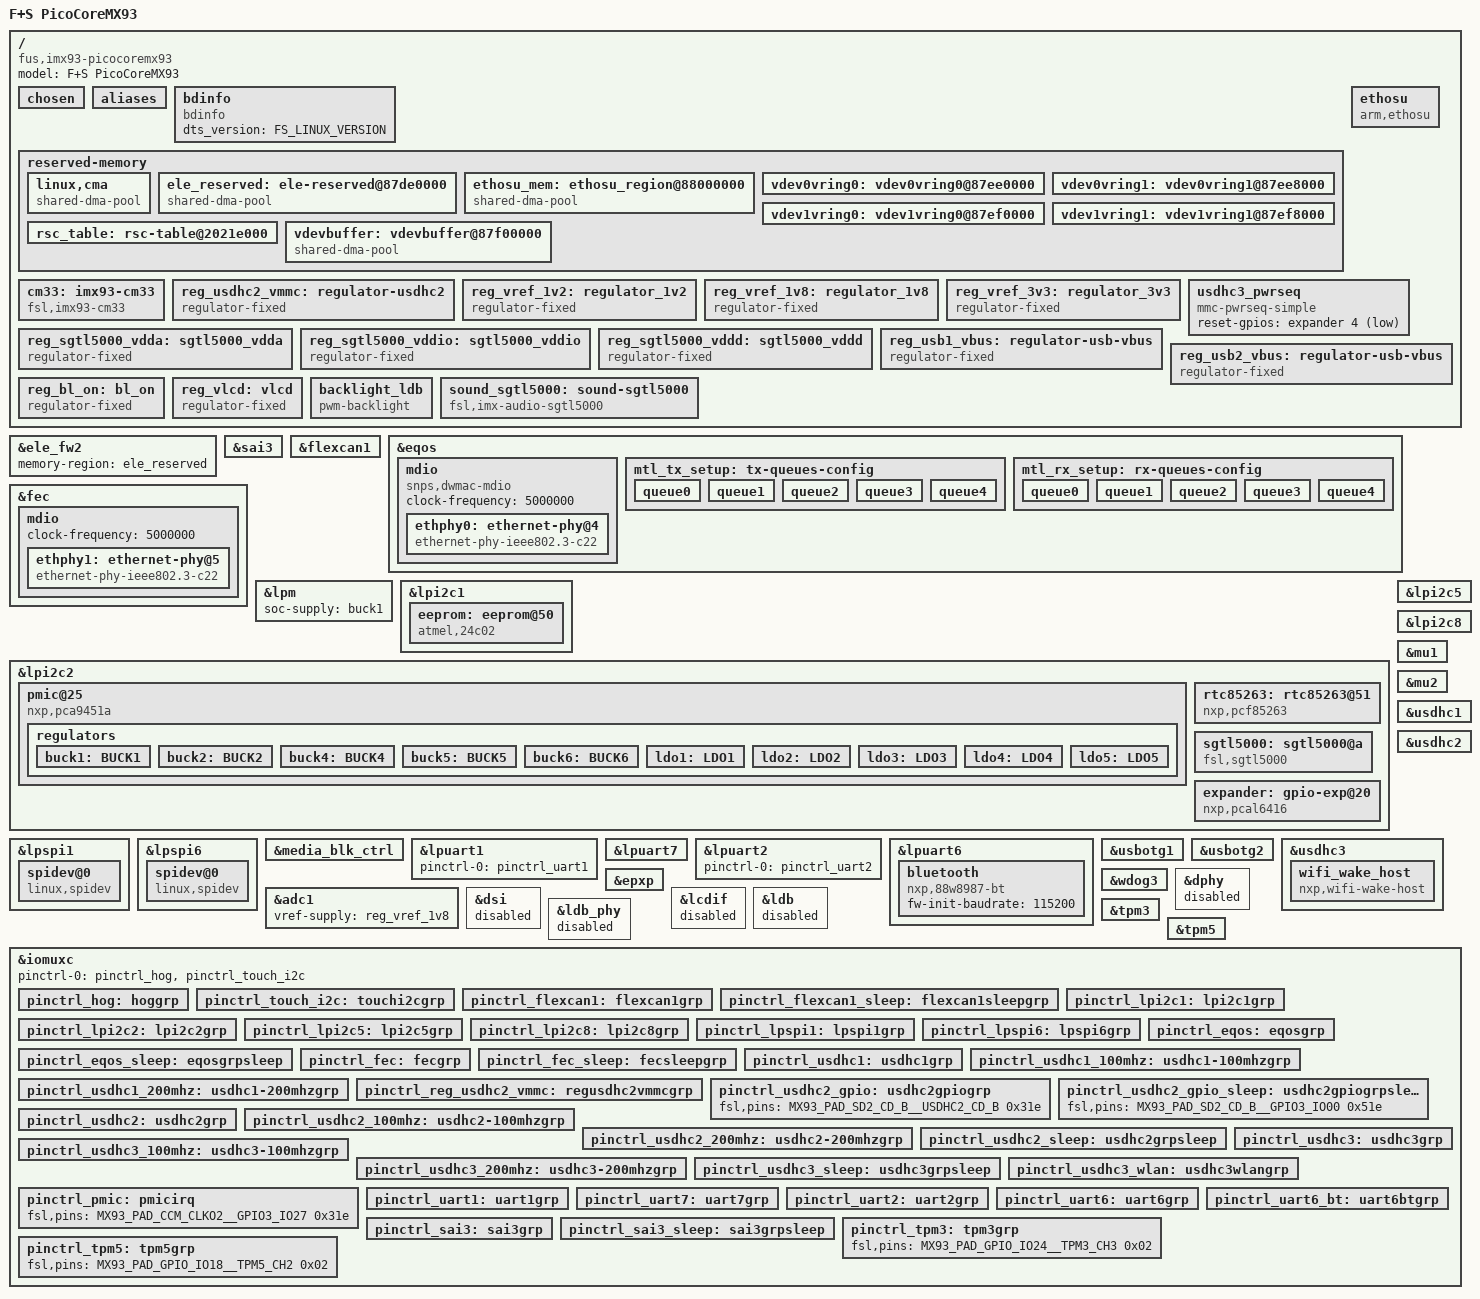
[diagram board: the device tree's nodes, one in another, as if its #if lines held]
/*
 * Copyright (C) 2024 F&S Elektronik Systeme GmbH
 *
 * This program is free software; you can redistribute it and/or modify
 * it under the terms of the GNU General Public License version 2 as
 * published by the Free Software Foundation.
 */

/dts-v1/;

#include <dt-bindings/usb/pd.h>
#include <dt-bindings/pwm/pwm.h>
#include <dt-bindings/rtc/pcf85363.h>
#include "../freescale/imx93.dtsi"
#include <fsversion.h>

&ele_fw2 {
	memory-region = <&ele_reserved>;
};

/ {
	model = "F+S PicoCoreMX93";
	compatible = "fus,imx93-picocoremx93", "fsl,imx93";

	chosen {
		bootargs = "console=ttyLP6,115200";
		stdout-path = &lpuart7;
	};

	aliases {
		ethernet0 = &eqos;
		ethernet1 = &fec;
		spi0 = &lpspi3;
		spi1 = &lpspi6;
		eeprom = &eeprom;
#ifdef CONFIG_PICOCOREMX93_EXT_RTC
		rtcpcf85263 = &rtc85263;
#endif
		sd_a = &usdhc2;
		sd_b = &usdhc3;
		sd_c = &usdhc1;
		adc  = &adc1;
	};

	/* -------------------- BOARD INFO -------------------- */
	bdinfo: bdinfo {
		compatible = "bdinfo";
		dts_version = FS_LINUX_VERSION;
	};

	reserved-memory {
		#address-cells = <2>;
		#size-cells = <2>;
		ranges;

		linux,cma {
			compatible = "shared-dma-pool";
			reusable;
			alloc-ranges = <0 0x80000000 0 0x40000000>;
			size = <0 0x10000000>;
			linux,cma-default;
		};


		ele_reserved: ele-reserved@87de0000 {
			compatible = "shared-dma-pool";
			reg = <0 0x87de0000 0 0x100000>;
			no-map;
		};

#ifdef SUPPORT_RPMSG
		ethosu_mem: ethosu_region@88000000 {
			compatible = "shared-dma-pool";
			reusable;
			reg = <0x0 0x88000000 0x0 0x8000000>;
		};

		vdev0vring0: vdev0vring0@87ee0000 {
			reg = <0 0x87ee0000 0 0x8000>;
			no-map;
		};

		vdev0vring1: vdev0vring1@87ee8000 {
			reg = <0 0x87ee8000 0 0x8000>;
			no-map;
		};

		vdev1vring0: vdev1vring0@87ef0000 {
			reg = <0 0x87ef0000 0 0x8000>;
			no-map;
		};

		vdev1vring1: vdev1vring1@87ef8000 {
			reg = <0 0x87ef8000 0 0x8000>;
			no-map;
		};

		rsc_table: rsc-table@2021e000 {
			reg = <0 0x2021e000 0 0x1000>;
			no-map;
		};

		vdevbuffer: vdevbuffer@87f00000 {
			compatible = "shared-dma-pool";
			reg = <0 0x87f00000 0 0x100000>;
			no-map;
		};
#endif /* SUPPORT_RPMSG */
	};

#ifdef SUPPORT_M33
	cm33: imx93-cm33 {
		compatible = "fsl,imx93-cm33";
#ifdef SUPPORT_RPMSG
		mbox-names = "tx", "rx", "rxdb";
		mboxes = <&mu1 0 1
			  &mu1 1 1
			  &mu1 3 1>;
		memory-region = <&vdevbuffer>, <&vdev0vring0>, <&vdev0vring1>,
				<&vdev1vring0>, <&vdev1vring1>, <&rsc_table>;
#endif /* SUPPORT_RPMSG */
		fsl,startup-delay-ms = <500>;
	};

	ethosu {
		compatible = "arm,ethosu";
		fsl,cm33-proc = <&cm33>;
		memory-region = <&ethosu_mem>;
		power-domains = <&mlmix>;
	};
#endif /* SUPPORT_M33 */

#ifdef CONFIG_PICOCOREMX93_SD_A
	reg_usdhc2_vmmc: regulator-usdhc2 {
		compatible = "regulator-fixed";
		pinctrl-names = "default";
		pinctrl-0 = <&pinctrl_reg_usdhc2_vmmc>;
		regulator-name = "VSD_3V3";
		regulator-min-microvolt = <3300000>;
		regulator-max-microvolt = <3300000>;
		gpio = <&gpio3 7 GPIO_ACTIVE_HIGH>;
		startup-delay-us = <100>;
		off-on-delay-us = <12000>;
		enable-active-high;
	};
#endif /* CONFIG_PICOCOREMX93_SD_A */

	reg_vref_1v2: regulator_1v2 {
		compatible = "regulator-fixed";
		regulator-name = "vref-1V2";
		regulator-min-microvolt = <1200000>;
		regulator-max-microvolt = <1200000>;
		regulator-always-on;
	};

	reg_vref_1v8: regulator_1v8 {
		compatible = "regulator-fixed";
		regulator-name = "vref-1V8";
		regulator-min-microvolt = <1800000>;
		regulator-max-microvolt = <1800000>;
		regulator-always-on;
	};

	reg_vref_3v3: regulator_3v3 {
		compatible = "regulator-fixed";
		regulator-name = "vref-3V3";
		regulator-min-microvolt = <3300000>;
		regulator-max-microvolt = <3300000>;
		regulator-always-on;
	};
#ifdef CONFIG_PICOCOREMX93_SD_B
	usdhc3_pwrseq: usdhc3_pwrseq {
		compatible = "mmc-pwrseq-simple";
		reset-gpios = <&expander 4 GPIO_ACTIVE_LOW>;
	};
#endif /* CONFIG_PICOCOREMX93_SD_B */
#ifdef CONFIG_PICOCOREMX93_SGTL5000_AUDIO
	/* SGTL5000 analog voltage */
	reg_sgtl5000_vdda: sgtl5000_vdda {
		compatible = "regulator-fixed";
		regulator-name = "VDDA-supply";
		regulator-min-microvolt = <3300000>;
		regulator-max-microvolt = <3300000>;
		regulator-always-on;
	};

	/* SGTL5000 I/O voltage */
	reg_sgtl5000_vddio: sgtl5000_vddio {
		compatible = "regulator-fixed";
		regulator-name = "VDDIO-supply";
		regulator-min-microvolt = <3300000>;
		regulator-max-microvolt = <3300000>;
		regulator-always-on;
	};

	/* SGTL5000 internal digital voltage */
	reg_sgtl5000_vddd: sgtl5000_vddd {
		compatible = "regulator-fixed";
		regulator-name = "VDDD-supply";
		regulator-min-microvolt = <1800000>;
		regulator-max-microvolt = <1800000>;
		regulator-always-on;
	};
#endif /* CONFIG_PICOCOREMX93_SGTL5000_AUDIO */

	reg_usb1_vbus: regulator-usb-vbus {
		compatible = "regulator-fixed";
		regulator-name = "usb1_vbus";
		regulator-min-microvolt = <3300000>;
		regulator-max-microvolt = <3300000>;
		gpio = <&expander 3 GPIO_ACTIVE_HIGH>;
		enable-active-high;
	};

	reg_usb2_vbus: regulator-usb-vbus {
		compatible = "regulator-fixed";
		regulator-name = "usb2_vbus";
		regulator-min-microvolt = <3300000>;
		regulator-max-microvolt = <3300000>;
		gpio = <&expander 2 GPIO_ACTIVE_HIGH>;
		enable-active-high;
	};

#ifdef CONFIG_PICOCOREMX93_BL_CTRL
	reg_bl_on: bl_on {
		compatible = "regulator-fixed";
		regulator-name = "BL_ON";
		gpio = <&expander 5 GPIO_ACTIVE_HIGH>;
		regulator-min-microvolt = <3300000>;
		regulator-max-microvolt = <3300000>;
		enable-active-high;
	};
#endif /* CONFIG_PICOCOREMX93_BL_CTRL */

	/* LCD power on voltage */
	reg_vlcd: vlcd {
		compatible = "regulator-fixed";
		regulator-name = "VLCD_ON";
		gpio = <&expander 6 GPIO_ACTIVE_HIGH>;
		regulator-min-microvolt = <3300000>;
		regulator-max-microvolt = <3300000>;
		enable-active-high;
	};

#ifdef CONFIG_PICOCOREMX93_BL_CTRL
	backlight_ldb: backlight_ldb {
		compatible = "pwm-backlight";
		#pwm-cells = <3>;
		pwms = <&tpm5 2 5263157 PWM_POLARITY_INVERTED>;
		power-supply = <&reg_bl_on>;
		brightness-levels = <0 1 5 10 18 28 41 56
			                 73 92 113 137 163 192 222 255>;
		default-brightness-level = <14>;
		fb-names = "mxs-lcdif0";
		status = "okay";
	};
#endif /* CONFIG_PICOCOREMX93_BL_CTRL */

#ifdef CONFIG_PICOCOREMX93_SGTL5000_AUDIO
	sound_sgtl5000: sound-sgtl5000 {
		compatible = "fsl,imx-audio-sgtl5000";
		model = "imx-sgtl5000";
		audio-cpu = <&sai3>;
		audio-codec = <&sgtl5000>;
		audio-routing =
			"LINE_IN", "Line In Jack",
			"Mic Jack", "Mic Bias",
			"MIC_IN", "Mic Jack",
			"Line Out Jack", "LINE_OUT",
			"Headphone Jack", "HP_OUT";
	};
#endif /* CONFIG_PICOCOREMX93_SGTL5000_AUDIO */
};

#ifdef CONFIG_PICOCOREMX93_I2S_A
&sai3 {
	pinctrl-names = "default";
	pinctrl-0 = <&pinctrl_sai3>;
	assigned-clocks = <&clk IMX93_CLK_SAI3>;
	assigned-clock-parents = <&clk IMX93_CLK_AUDIO_PLL>;
	assigned-clock-rates = <24576000>;
	fsl,sai-mclk-direction-output;
	status = "okay";
};
#endif /* CONFIG_PICOCOREMX93_I2S_A */

#ifdef CONFIG_PICOCOREMX93_CAN
&flexcan1 {
	pinctrl-names = "default", "sleep";
	pinctrl-0 = <&pinctrl_flexcan1>;
	pinctrl-1 = <&pinctrl_flexcan1_sleep>;
	status = "okay";
};
#endif /* CONFIG_PICOCOREMX93_CAN */

/* ETH_A */
&eqos {
	pinctrl-names = "default", "sleep";
	pinctrl-0 = <&pinctrl_eqos>;
	pinctrl-1 = <&pinctrl_eqos_sleep>;
	phy-mode = "rgmii-id";
	phy-handle = <&ethphy0>;
	snps,force_thresh_dma_mode;
	snps,mtl-tx-config = <&mtl_tx_setup>;
	snps,mtl-rx-config = <&mtl_rx_setup>;
	status = "okay";

	mdio {
		compatible = "snps,dwmac-mdio";
		#address-cells = <1>;
		#size-cells = <0>;
		clock-frequency = <5000000>;

		ethphy0: ethernet-phy@4 {
			compatible = "ethernet-phy-ieee802.3-c22";
			reg = <4>;
			rtl821x,clkout-disable;
			rtl821x,aldps-enable;
			rtl821x,ssc-rxc-enable;
			rtl821x,ssc-sysclk-enable;
			rtl821x,ssc-clkout-enable;
#ifdef CONFIG_PICOCOREMX93_ETH_A_LED_LINK
			rtl821x,led-link = <2>; // LED2 for link indication
#endif
#ifdef CONFIG_PICOCOREMX93_ETH_A_LED_ACT
			rtl821x,led-act = <1>; // LED1 for activity
#endif
			reset-gpios = <&expander 0 GPIO_ACTIVE_LOW>;
			reset-assert-us = <10000>;
			reset-deassert-us = <50000>;
			interrupt-parent = <&gpio2>;
			interrupts = <28 IRQ_TYPE_LEVEL_LOW>;
			eee-broken-1000t;
		};
	};

	mtl_tx_setup: tx-queues-config {
		snps,tx-queues-to-use = <5>;
		snps,tx-sched-sp;
		queue0 {
			snps,dcb-algorithm;
			snps,priority = <0x1>;
		};
		queue1 {
			snps,dcb-algorithm;
			snps,priority = <0x2>;
		};
		queue2 {
			snps,dcb-algorithm;
			snps,priority = <0x4>;
		};
		queue3 {
			snps,dcb-algorithm;
			snps,priority = <0x8>;
		};
		queue4 {
			snps,dcb-algorithm;
			snps,priority = <0xf0>;
		};
	};

	mtl_rx_setup: rx-queues-config {
		snps,rx-queues-to-use = <5>;
		snps,rx-sched-sp;
		queue0 {
			snps,dcb-algorithm;
			snps,priority = <0x1>;
			snps,map-to-dma-channel = <0>;
		};
		queue1 {
			snps,dcb-algorithm;
			snps,priority = <0x2>;
			snps,map-to-dma-channel = <1>;
		};
		queue2 {
			snps,dcb-algorithm;
			snps,priority = <0x4>;
			snps,map-to-dma-channel = <2>;
		};
		queue3 {
			snps,dcb-algorithm;
			snps,priority = <0x8>;
			snps,map-to-dma-channel = <3>;
		};
		queue4 {
			snps,dcb-algorithm;
			snps,priority = <0xf0>;
			snps,map-to-dma-channel = <4>;
		};
	};
};

/* ETH_B */
&fec {
	pinctrl-names = "default", "sleep";
	pinctrl-0 = <&pinctrl_fec>;
	pinctrl-1 = <&pinctrl_fec_sleep>;
	phy-mode = "rgmii-id";
	phy-handle = <&ethphy1>;
	fsl,magic-packet;
	status = "okay";

	mdio {
		#address-cells = <1>;
		#size-cells = <0>;
		clock-frequency = <5000000>;

		ethphy1: ethernet-phy@5 {
			compatible = "ethernet-phy-ieee802.3-c22";
			reg = <5>;
			rtl821x,clkout-disable;
			rtl821x,aldps-enable;
			rtl821x,ssc-rxc-enable;
			rtl821x,ssc-sysclk-enable;
			rtl821x,ssc-clkout-enable;
#ifdef CONFIG_PICOCOREMX93_ETH_B_LED_LINK
			rtl821x,led-link = <2>; // LED2 for link indication
#endif
#ifdef CONFIG_PICOCOREMX93_ETH_B_LED_ACT
			rtl821x,led-act = <1>; // LED1 for activity
#endif
			reset-gpios = <&expander 1 GPIO_ACTIVE_LOW>;
			reset-assert-us = <10000>;
			reset-deassert-us = <50000>;
			interrupt-parent = <&gpio2>;
			interrupts = <29 IRQ_TYPE_LEVEL_LOW>;
			eee-broken-1000t;
		};
	};
};

&lpm {
	soc-supply = <&buck1>;
	status = "okay";
};

#ifdef CONFIG_PICOCOREMX93_I2C_A
&lpi2c1 {
	#address-cells = <1>;
	#size-cells = <0>;
	clock-frequency = <400000>;
	pinctrl-names = "default", "sleep";
	pinctrl-0 = <&pinctrl_lpi2c1>;
	pinctrl-1 = <&pinctrl_lpi2c1>;
	status = "okay";

	eeprom: eeprom@50 {
		compatible = "atmel,24c02";
		vcc-supply = <&reg_vref_3v3>;
		reg = <0x50>;
		pagesize = <32>;
	};
};
#endif /* CONFIG_PICOCOREMX93_I2C_A */

#ifdef CONFIG_PICOCOREMX93_I2C_D
/* I2C_D */
&lpi2c2 {
	#address-cells = <1>;
	#size-cells = <0>;
	clock-frequency = <400000>;
	pinctrl-names = "default", "sleep";
	pinctrl-0 = <&pinctrl_lpi2c2>;
	pinctrl-1 = <&pinctrl_lpi2c2>;
	status = "okay";

	pmic@25 {
		compatible = "nxp,pca9451a";
		reg = <0x25>;
		pinctrl-names = "default";
		pinctrl-0 = <&pinctrl_pmic>;
		interrupt-parent = <&gpio3>;
		interrupts = <27 IRQ_TYPE_EDGE_FALLING>;

		regulators {
			buck1: BUCK1 {
				regulator-name = "BUCK1";
				regulator-min-microvolt = <650000>;
				regulator-max-microvolt = <2237500>;
				regulator-boot-on;
				regulator-always-on;
				regulator-ramp-delay = <3125>;
			};

			buck2: BUCK2 {
				regulator-name = "BUCK2";
				regulator-min-microvolt = <600000>;
				regulator-max-microvolt = <2187500>;
				regulator-boot-on;
				regulator-always-on;
				regulator-ramp-delay = <3125>;
			};

			buck4: BUCK4{
				regulator-name = "BUCK4";
				regulator-min-microvolt = <600000>;
				regulator-max-microvolt = <3400000>;
				regulator-boot-on;
				regulator-always-on;
			};

			buck5: BUCK5{
				regulator-name = "BUCK5";
				regulator-min-microvolt = <600000>;
				regulator-max-microvolt = <3400000>;
				regulator-boot-on;
				regulator-always-on;
			};

			buck6: BUCK6 {
				regulator-name = "BUCK6";
				regulator-min-microvolt = <600000>;
				regulator-max-microvolt = <3400000>;
				regulator-boot-on;
				regulator-always-on;
			};

			ldo1: LDO1 {
				regulator-name = "LDO1";
				regulator-min-microvolt = <1600000>;
				regulator-max-microvolt = <1900000>;
				regulator-boot-on;
				regulator-always-on;
			};

			ldo2: LDO2 {
				regulator-name = "LDO2";
				regulator-min-microvolt = <800000>;
				regulator-max-microvolt = <1150000>;
				regulator-boot-on;
				regulator-always-on;
			};

			ldo3: LDO3 {
				regulator-name = "LDO3";
				regulator-min-microvolt = <800000>;
				regulator-max-microvolt = <3300000>;
				regulator-boot-on;
				regulator-always-on;
			};

			ldo4: LDO4 {
				regulator-name = "LDO4";
				regulator-min-microvolt = <800000>;
				regulator-max-microvolt = <3300000>;
				regulator-boot-on;
				regulator-always-on;
			};

			ldo5: LDO5 {
				regulator-name = "LDO5";
				regulator-min-microvolt = <1800000>;
				regulator-max-microvolt = <3300000>;
				regulator-boot-on;
				regulator-always-on;
			};
		};
	};

#ifdef CONFIG_PICOCOREMX93_EXT_RTC
	rtc85263: rtc85263@51 {
		compatible = "nxp,pcf85263";
		reg = <0x51>;
		clock-out = <PCF85363_COF_32768Hz>;
		quartz-load-femtofarads = <PCF85363_CAP_12p5pF>;
		quartz-drive-strength = <PCF85363_OSC_DRIVE_LOW>;
	};
#endif

#ifdef CONFIG_PICOCOREMX93_SGTL5000_AUDIO
	sgtl5000: sgtl5000@a {
		#sound-dai-cells = <0>;
		compatible = "fsl,sgtl5000";
		clocks = <&clk IMX93_CLK_SAI3_GATE>;
		reg = <0xa>;
		mono2both;
		VDDA-supply = <&reg_sgtl5000_vdda>;
		VDDIO-supply = <&reg_sgtl5000_vddio>;
		VDDD-supply = <&reg_sgtl5000_vddd>;
		status = "okay";
	};
#endif

		expander: gpio-exp@20 {
			compatible = "nxp,pcal6416";
			reg = <0x20>;
			vcc-supply = <&reg_vref_3v3>;
			gpio-controller;
			#gpio-cells = <2>;
			ngpios = <16>;
			interrupt-parent = <&gpio4>;
			interrupts = <29 IRQ_TYPE_LEVEL_LOW>;
			gpio-line-names = "eth_a_rst",
				"eth_b_rst", "usb_host_pwr",
				"usb_otg_pwr", "wlan_rst",
				"disp_bl_en", "disp_vdd_en", /* bl_on, vlcd_on */
				"gpio_j1_52", "gpio_j1_54",
				"gpio_j2_65", "gpio_j2_67",
				"gpio_j2_69", "gpio_j2_83",
				"gpio_j2_85", "gpio_j1_44",
				"gpio_j1_46";
		};
};
#endif /* CONFIG_PICOCOREMX93_I2C_D */

#ifdef CONFIG_PICOCOREMX93_I2C_C
&lpi2c5 {
	#address-cells = <1>;
	#size-cells = <0>;
	clock-frequency = <400000>;
	pinctrl-names = "default", "sleep";
	pinctrl-0 = <&pinctrl_lpi2c5>;
	pinctrl-1 = <&pinctrl_lpi2c5>;

	status = "okay";
};
#endif /* CONFIG_PICOCOREMX93_I2C_C */

#ifdef CONFIG_PICOCOREMX93_I2C_B
&lpi2c8 {
	#address-cells = <1>;
	#size-cells = <0>;
	clock-frequency = <400000>;
	pinctrl-names = "default", "sleep";
	pinctrl-0 = <&pinctrl_lpi2c8>;
	pinctrl-1 = <&pinctrl_lpi2c8>;

	status = "okay";
};
#endif /* CONFIG_PICOCOREMX93_I2C_B */

#ifdef CONFIG_PICOCOREMX93_SPI_B
&lpspi1 {
	fsl,spi-num-chipselects = <1>;
	pinctrl-names = "default", "sleep";
	pinctrl-0 = <&pinctrl_lpspi1>;
	pinctrl-1 = <&pinctrl_lpspi1>;
	cs-gpios = <&gpio1 11 GPIO_ACTIVE_LOW>;
	status = "okay";

	spidev@0 {
		compatible = "linux,spidev";
		spi-max-frequency = <20000000>;
		reg = <0>;
		status = "okay";
	};
};
#endif /* CONFIG_PICOCOREMX93_SPI_B */

#ifdef CONFIG_PICOCOREMX93_SPI_A
&lpspi6 {
	fsl,spi-num-chipselects = <1>;
	pinctrl-names = "default", "sleep";
	pinctrl-0 = <&pinctrl_lpspi6>;
	pinctrl-1 = <&pinctrl_lpspi6>;
	cs-gpios = <&gpio2 1 GPIO_ACTIVE_LOW>;
	status = "okay";

	spidev@0 {
		compatible = "linux,spidev";
		spi-max-frequency = <20000000>;
		reg = <0>;
		status = "okay";
	};
};
#endif /* CONFIG_PICOCOREMX93_SPI_A */

&media_blk_ctrl {
	status = "okay";
};

&mu1 {
	status = "okay";
};

&mu2 {
	status = "okay";
};

#ifdef CONFIG_PICOCOREMX93_UART_C
&lpuart1 {
	pinctrl-names = "default";
	pinctrl-0 = <&pinctrl_uart1>;
	status = "okay";
};
#endif /* CONFIG_PICOCOREMX93_UART_C */

#ifdef CONFIG_PICOCOREMX93_UART_A
&lpuart7 { /* console */
	pinctrl-names = "default";
	pinctrl-0 = <&pinctrl_uart7>;
#ifdef CONFIG_PICOCOREMX93_UART_A_RTSCTS
	fsl,uart-has-rtscts;
#endif /* CONFIG_PICOCOREMX93_UART_A_RTSCTS */
	status = "okay";
};
#endif

#ifdef CONFIG_PICOCOREMX93_UART_D
&lpuart2 {
	pinctrl-names = "default";
	pinctrl-0 = <&pinctrl_uart2>;
	status = "okay";
};
#endif

#ifdef CONFIG_PICOCOREMX93_UART_B
&lpuart6 {
	/* BT */
	pinctrl-names = "default";
	pinctrl-0 = <&pinctrl_uart6>, <&pinctrl_uart6_bt>;
	status = "okay";
#ifdef CONFIG_PICOCOREMX93_UART_B_RTSCTS
	uart-has-rtscts;
#endif /* CONFIG_PICOCOREMX93_UART_B_RTSCTS */
#ifdef CONFIG_PICOCOREMX93_UART_B_BT
	bluetooth {
		compatible = "nxp,88w8987-bt";
		fw-init-baudrate = <115200>;
	};
#endif /* CONFIG_PICOCOREMX93_UART_B_BT */
};
#endif /* CONFIG_PICOCOREMX93_UART_B */

&usbotg1 {
	dr_mode = "otg";
	vbus-supply = <&reg_usb1_vbus>;
	hnp-disable;
	srp-disable;
	adp-disable;
	disable-over-current;
	samsung,picophy-pre-emp-curr-control = <3>;
	samsung,picophy-dc-vol-level-adjust = <7>;
	status = "okay";
};

&usbotg2 {
	dr_mode = "host";
	vbus-supply = <&reg_usb2_vbus>;
	disable-over-current;
	samsung,picophy-pre-emp-curr-control = <3>;
	samsung,picophy-dc-vol-level-adjust = <7>;
	status = "okay";
};

/* SD_C - eMMC */
&usdhc1 {
	pinctrl-names = "default", "state_100mhz", "state_200mhz";
	pinctrl-0 = <&pinctrl_usdhc1>;
	pinctrl-1 = <&pinctrl_usdhc1_100mhz>;
	pinctrl-2 = <&pinctrl_usdhc1_200mhz>;
	bus-width = <8>;
	non-removable;
	status = "okay";
};

#ifdef CONFIG_PICOCOREMX93_SD_A
&usdhc2 {
	pinctrl-names = "default", "state_100mhz", "state_200mhz", "sleep";
	pinctrl-0 = <&pinctrl_usdhc2>, <&pinctrl_usdhc2_gpio>;
	pinctrl-1 = <&pinctrl_usdhc2_100mhz>, <&pinctrl_usdhc2_gpio>;
	pinctrl-2 = <&pinctrl_usdhc2_200mhz>, <&pinctrl_usdhc2_gpio>;
	pinctrl-3 = <&pinctrl_usdhc2_sleep>, <&pinctrl_usdhc2_gpio_sleep>;
	vmmc-supply = <&reg_usdhc2_vmmc>;
	bus-width = <4>;
	disable-wp;
	status = "okay";
};
#endif /* CONFIG_PICOCOREMX93_SD_A */

#ifdef CONFIG_PICOCOREMX93_SD_B
&usdhc3 {
	pinctrl-names = "default", "state_100mhz", "state_200mhz", "sleep";
	pinctrl-0 = <&pinctrl_usdhc3>, <&pinctrl_usdhc3_wlan>;
	pinctrl-1 = <&pinctrl_usdhc3_100mhz>, <&pinctrl_usdhc3_wlan>;
	pinctrl-2 = <&pinctrl_usdhc3_200mhz>, <&pinctrl_usdhc3_wlan>;
	pinctrl-3 = <&pinctrl_usdhc3_sleep>, <&pinctrl_usdhc3_wlan>;
	mmc-pwrseq = <&usdhc3_pwrseq>;
	vmmc-supply = <&reg_vref_3v3>;
	vqmmc-supply = <&reg_vref_1v8>;
	vqmmc-1-8-v;
	bus-width = <4>;
	keep-power-in-suspend;
	non-removable;
	wakeup-source;
// 	fsl,sdio-async-interrupt-enabled;
//	pm-ignore-notify;
	status = "okay";

	wifi_wake_host {
		compatible = "nxp,wifi-wake-host";
		interrupt-parent = <&gpio3>;
		interrupts = <26 IRQ_TYPE_LEVEL_LOW>;
		interrupt-names = "host-wake";
	};
};
#endif /* CONFIG_PICOCOREMX93_SD_B */

#ifdef CONFIG_PICOCOREMX93_ADC
&adc1 {
	vref-supply = <&reg_vref_1v8>;
	status = "okay";
};
#endif /* CONFIG_PICOCOREMX93_ADC */

&epxp {
	status = "okay";
};

&wdog3 {
	status = "okay";
};

&dphy {
	status = "disabled";
};

&dsi {
	status = "disabled";
};

&lcdif {
	status = "disabled";
};

&ldb {
	status = "disabled";
};

&ldb_phy {
	status = "disabled";
};

#ifdef CONFIG_PICOCOREMX93_PWM_A
&tpm3 {
	pinctrl-names = "default";
	pinctrl-0 = <&pinctrl_tpm3>;
	#pwm-cells = <3>;
	keep-power;
	status = "okay";
};
#endif /* CONFIG_PICOCOREMX93_PWM_A */

#ifdef CONFIG_PICOCOREMX93_BL_CTRL
&tpm5 {
	pinctrl-names = "default";
	pinctrl-0 = <&pinctrl_tpm5>;
	#pwm-cells = <3>;
	keep-power;
	status = "okay";
};
#endif /* CONFIG_PICOCOREMX93_BL_CTRL */

&iomuxc {
	pinctrl-names = "default";
	pinctrl-0 = <&pinctrl_hog>, <&pinctrl_touch_i2c>;

	pinctrl_hog: hoggrp {
		fsl,pins = <
#ifndef CONFIG_PICOCOREMX93_SPI_B
			/* GPIO pins if SPI_B is not used */
			MX93_PAD_SAI1_TXFS__GPIO1_IO11		0x3fe
			MX93_PAD_SAI1_TXC__GPIO1_IO12		0x3fe
			MX93_PAD_SAI1_RXD0__GPIO1_IO14		0x3fe
			MX93_PAD_SAI1_TXD0__GPIO1_IO13		0x3fe
#endif
			/* GPIO expander irq */
			MX93_PAD_CCM_CLKO4__GPIO4_IO29		0x3fe
			/* GPIO_J1_7, MIPI_RESET */
			MX93_PAD_GPIO_IO14__GPIO2_IO14		0x3fe
		>;
	};

	pinctrl_touch_i2c: touchi2cgrp {
	fsl,pins = <
			/* I2C_B_IRQ */
			MX93_PAD_GPIO_IO15__GPIO2_IO15		0x3fe
			/* GPIO_J1_2, TOUCH_RESET */
			MX93_PAD_GPIO_IO19__GPIO2_IO19		0x3fe
		>;
	};

#ifdef CONFIG_PICOCOREMX93_CAN
	pinctrl_flexcan1: flexcan1grp {
		fsl,pins = <
			MX93_PAD_PDM_CLK__CAN1_TX	0x139e
			MX93_PAD_PDM_BIT_STREAM0__CAN1_RX	0x139e
		>;
	};

	pinctrl_flexcan1_sleep: flexcan1sleepgrp {
		fsl,pins = <
			MX93_PAD_PDM_CLK__GPIO1_IO08	0x31e
			MX93_PAD_PDM_BIT_STREAM0__GPIO1_IO09	0x31e
		>;
	};
#endif

#ifdef CONFIG_PICOCOREMX93_I2C_A
	pinctrl_lpi2c1: lpi2c1grp {
		fsl,pins = <
			MX93_PAD_I2C1_SCL__LPI2C1_SCL			0x40000b9e
			MX93_PAD_I2C1_SDA__LPI2C1_SDA			0x40000b9e
		>;
	};
#endif /* CONFIG_PICOCOREMX93_I2C_A */

#ifdef CONFIG_PICOCOREMX93_I2C_D
	pinctrl_lpi2c2: lpi2c2grp {
		fsl,pins = <
			MX93_PAD_I2C2_SCL__LPI2C2_SCL			0x40000b9e
			MX93_PAD_I2C2_SDA__LPI2C2_SDA			0x40000b9e
		>;
	};
#endif /* CONFIG_PICOCOREMX93_I2C_D */

#ifdef CONFIG_PICOCOREMX93_I2C_C
	pinctrl_lpi2c5: lpi2c5grp {
		fsl,pins = <
			MX93_PAD_GPIO_IO23__LPI2C5_SCL			0x40000b9e
			MX93_PAD_GPIO_IO22__LPI2C5_SDA			0x40000b9e
		>;
	};
#endif /* CONFIG_PICOCOREMX93_I2C_C */

#ifdef CONFIG_PICOCOREMX93_I2C_B
	pinctrl_lpi2c8: lpi2c8grp {
		fsl,pins = <
			MX93_PAD_GPIO_IO13__LPI2C8_SCL			0x40000b9e
			MX93_PAD_GPIO_IO12__LPI2C8_SDA			0x40000b9e
		>;
	};
#endif /* CONFIG_PICOCOREMX93_I2C_B */

#ifdef CONFIG_PICOCOREMX93_SPI_B
	pinctrl_lpspi1: lpspi1grp {
		fsl,pins = <
			/*MX93_PAD_SAI1_TXFS__LPSPI1_PCS0		0x3fe */
			MX93_PAD_SAI1_TXFS__GPIO1_IO11		0x3fe
			MX93_PAD_SAI1_TXC__LPSPI1_SIN		0x3fe
			MX93_PAD_SAI1_RXD0__LPSPI1_SOUT		0x3fe
			MX93_PAD_SAI1_TXD0__LPSPI1_SCK		0x3fe
		>;
	};
#endif /* CONFIG_PICOCOREMX93_SPI_B */

#ifdef CONFIG_PICOCOREMX93_SPI_A
	pinctrl_lpspi6: lpspi6grp {
		fsl,pins = <
			/* MX93_PAD_GPIO_IO00__LPSPI6_PCS0	0x3fe */
			MX93_PAD_GPIO_IO00__GPIO2_IO00	0x3fe
			MX93_PAD_GPIO_IO01__LPSPI6_SIN	0x3fe
			MX93_PAD_GPIO_IO02__LPSPI6_SOUT	0x3fe
			MX93_PAD_GPIO_IO03__LPSPI6_SCK	0x3fe
		>;
	};
#endif /* CONFIG_PICOCOREMX93_SPI_A */

	pinctrl_eqos: eqosgrp {
		fsl,pins = <
			MX93_PAD_ENET1_MDC__ENET_QOS_MDC			0x57e
			MX93_PAD_ENET1_MDIO__ENET_QOS_MDIO			0x57e
			MX93_PAD_ENET1_RD0__ENET_QOS_RGMII_RD0			0x57e
			MX93_PAD_ENET1_RD1__ENET_QOS_RGMII_RD1			0x57e
			MX93_PAD_ENET1_RD2__ENET_QOS_RGMII_RD2			0x57e
			MX93_PAD_ENET1_RD3__ENET_QOS_RGMII_RD3			0x57e
			MX93_PAD_ENET1_RXC__CCM_ENET_QOS_CLOCK_GENERATE_RX_CLK	0x58e
			MX93_PAD_ENET1_RX_CTL__ENET_QOS_RGMII_RX_CTL		0x57e
			MX93_PAD_ENET1_TD0__ENET_QOS_RGMII_TD0			0x57e
			MX93_PAD_ENET1_TD1__ENET_QOS_RGMII_TD1			0x57e
			MX93_PAD_ENET1_TD2__ENET_QOS_RGMII_TD2			0x57e
			MX93_PAD_ENET1_TD3__ENET_QOS_RGMII_TD3			0x57e
			MX93_PAD_ENET1_TXC__CCM_ENET_QOS_CLOCK_GENERATE_TX_CLK	0x58e
			MX93_PAD_ENET1_TX_CTL__ENET_QOS_RGMII_TX_CTL		0x57e
			/* ETH_A_PHY_IRQ */
			MX93_PAD_GPIO_IO28__GPIO2_IO28		0x31e
		>;
	};

	pinctrl_eqos_sleep: eqosgrpsleep {
		fsl,pins = <
			MX93_PAD_ENET1_MDC__GPIO4_IO00			0x31e
			MX93_PAD_ENET1_MDIO__GPIO4_IO01			0x31e
			MX93_PAD_ENET1_RD0__GPIO4_IO10			0x31e
			MX93_PAD_ENET1_RD1__GPIO4_IO11			0x31e
			MX93_PAD_ENET1_RD2__GPIO4_IO12			0x31e
			MX93_PAD_ENET1_RD3__GPIO4_IO13			0x31e
			MX93_PAD_ENET1_RXC__GPIO4_IO09			0x31e
			MX93_PAD_ENET1_RX_CTL__GPIO4_IO08			0x31e
			MX93_PAD_ENET1_TD0__GPIO4_IO05			0x31e
			MX93_PAD_ENET1_TD1__GPIO4_IO04			0x31e
			MX93_PAD_ENET1_TD2__GPIO4_IO03			0x31e
			MX93_PAD_ENET1_TD3__GPIO4_IO02			0x31e
			MX93_PAD_ENET1_TXC__GPIO4_IO07			0x31e
			MX93_PAD_ENET1_TX_CTL__GPIO4_IO06			0x31e
			/* ETH_A_PHY_IRQ */
			MX93_PAD_GPIO_IO28__GPIO2_IO28			0x31e
		>;
	};

	pinctrl_fec: fecgrp {
		fsl,pins = <
			MX93_PAD_ENET2_MDC__ENET1_MDC			0x57e
			MX93_PAD_ENET2_MDIO__ENET1_MDIO			0x57e
			MX93_PAD_ENET2_RD0__ENET1_RGMII_RD0		0x57e
			MX93_PAD_ENET2_RD1__ENET1_RGMII_RD1		0x57e
			MX93_PAD_ENET2_RD2__ENET1_RGMII_RD2		0x57e
			MX93_PAD_ENET2_RD3__ENET1_RGMII_RD3		0x57e
			MX93_PAD_ENET2_RXC__ENET1_RGMII_RXC		0x58e
			MX93_PAD_ENET2_RX_CTL__ENET1_RGMII_RX_CTL	0x57e
			MX93_PAD_ENET2_TD0__ENET1_RGMII_TD0		0x57e
			MX93_PAD_ENET2_TD1__ENET1_RGMII_TD1		0x57e
			MX93_PAD_ENET2_TD2__ENET1_RGMII_TD2		0x57e
			MX93_PAD_ENET2_TD3__ENET1_RGMII_TD3		0x57e
			MX93_PAD_ENET2_TXC__ENET1_RGMII_TXC		0x58e
			MX93_PAD_ENET2_TX_CTL__ENET1_RGMII_TX_CTL	0x57e
			/* ETH_B_PHY_IRQ */
			MX93_PAD_GPIO_IO29__GPIO2_IO29		0x31e
		>;
	};

	pinctrl_fec_sleep: fecsleepgrp {
		fsl,pins = <
			MX93_PAD_ENET2_MDC__GPIO4_IO14			0x51e
			MX93_PAD_ENET2_MDIO__GPIO4_IO15			0x51e
			MX93_PAD_ENET2_RD0__GPIO4_IO24			0x51e
			MX93_PAD_ENET2_RD1__GPIO4_IO25			0x51e
			MX93_PAD_ENET2_RD2__GPIO4_IO26			0x51e
			MX93_PAD_ENET2_RD3__GPIO4_IO27			0x51e
			MX93_PAD_ENET2_RXC__GPIO4_IO23			0x51e
			MX93_PAD_ENET2_RX_CTL__GPIO4_IO22			0x51e
			MX93_PAD_ENET2_TD0__GPIO4_IO19			0x51e
			MX93_PAD_ENET2_TD1__GPIO4_IO18			0x51e
			MX93_PAD_ENET2_TD2__GPIO4_IO17			0x51e
			MX93_PAD_ENET2_TD3__GPIO4_IO16			0x51e
			MX93_PAD_ENET2_TXC__GPIO4_IO21			0x51e
			MX93_PAD_ENET2_TX_CTL__GPIO4_IO20			0x51e
			/* ETH_B_PHY_IRQ */
			MX93_PAD_GPIO_IO29__GPIO2_IO29			0x31e
		>;
	};

	/* need to config the SION for data and cmd pad, refer to ERR052021 */
	pinctrl_usdhc1: usdhc1grp {
		fsl,pins = <
			MX93_PAD_SD1_CLK__USDHC1_CLK		0x1582
			MX93_PAD_SD1_CMD__USDHC1_CMD		0x40001382
			MX93_PAD_SD1_DATA0__USDHC1_DATA0	0x40001382
			MX93_PAD_SD1_DATA1__USDHC1_DATA1	0x40001382
			MX93_PAD_SD1_DATA2__USDHC1_DATA2	0x40001382
			MX93_PAD_SD1_DATA3__USDHC1_DATA3	0x40001382
			MX93_PAD_SD1_DATA4__USDHC1_DATA4	0x40001382
			MX93_PAD_SD1_DATA5__USDHC1_DATA5	0x40001382
			MX93_PAD_SD1_DATA6__USDHC1_DATA6	0x40001382
			MX93_PAD_SD1_DATA7__USDHC1_DATA7	0x40001382
			MX93_PAD_SD1_STROBE__USDHC1_STROBE	0x1582
		>;
	};

	/* need to config the SION for data and cmd pad, refer to ERR052021 */
	pinctrl_usdhc1_100mhz: usdhc1-100mhzgrp {
		fsl,pins = <
			MX93_PAD_SD1_CLK__USDHC1_CLK		0x158e
			MX93_PAD_SD1_CMD__USDHC1_CMD		0x4000138e
			MX93_PAD_SD1_DATA0__USDHC1_DATA0	0x4000138e
			MX93_PAD_SD1_DATA1__USDHC1_DATA1	0x4000138e
			MX93_PAD_SD1_DATA2__USDHC1_DATA2	0x4000138e
			MX93_PAD_SD1_DATA3__USDHC1_DATA3	0x4000138e
			MX93_PAD_SD1_DATA4__USDHC1_DATA4	0x4000138e
			MX93_PAD_SD1_DATA5__USDHC1_DATA5	0x4000138e
			MX93_PAD_SD1_DATA6__USDHC1_DATA6	0x4000138e
			MX93_PAD_SD1_DATA7__USDHC1_DATA7	0x4000138e
			MX93_PAD_SD1_STROBE__USDHC1_STROBE	0x158e
		>;
	};

	/* need to config the SION for data and cmd pad, refer to ERR052021 */
	pinctrl_usdhc1_200mhz: usdhc1-200mhzgrp {
		fsl,pins = <
			MX93_PAD_SD1_CLK__USDHC1_CLK		0x15fe
			MX93_PAD_SD1_CMD__USDHC1_CMD		0x400013fe
			MX93_PAD_SD1_DATA0__USDHC1_DATA0	0x400013fe
			MX93_PAD_SD1_DATA1__USDHC1_DATA1	0x400013fe
			MX93_PAD_SD1_DATA2__USDHC1_DATA2	0x400013fe
			MX93_PAD_SD1_DATA3__USDHC1_DATA3	0x400013fe
			MX93_PAD_SD1_DATA4__USDHC1_DATA4	0x400013fe
			MX93_PAD_SD1_DATA5__USDHC1_DATA5	0x400013fe
			MX93_PAD_SD1_DATA6__USDHC1_DATA6	0x400013fe
			MX93_PAD_SD1_DATA7__USDHC1_DATA7	0x400013fe
			MX93_PAD_SD1_STROBE__USDHC1_STROBE	0x15fe
		>;
	};

#ifdef CONFIG_PICOCOREMX93_SD_A
	pinctrl_reg_usdhc2_vmmc: regusdhc2vmmcgrp {
		fsl,pins = <
			MX93_PAD_SD2_RESET_B__GPIO3_IO07	0x31e
		>;
	};

	pinctrl_usdhc2_gpio: usdhc2gpiogrp {
		fsl,pins = <
			/* MX93_PAD_SD2_CD_B__GPIO3_IO00		0x31e */
			MX93_PAD_SD2_CD_B__USDHC2_CD_B		0x31e
		>;
	};

	pinctrl_usdhc2_gpio_sleep: usdhc2gpiogrpsleep {
		fsl,pins = <
			MX93_PAD_SD2_CD_B__GPIO3_IO00		0x51e
		>;
	};

	/* need to config the SION for data and cmd pad, refer to ERR052021 */
	pinctrl_usdhc2: usdhc2grp {
		fsl,pins = <
			MX93_PAD_SD2_CLK__USDHC2_CLK		0x178e
			MX93_PAD_SD2_CMD__USDHC2_CMD		0x4000139e
			MX93_PAD_SD2_DATA0__USDHC2_DATA0	0x40001382
			MX93_PAD_SD2_DATA1__USDHC2_DATA1	0x40001382
			MX93_PAD_SD2_DATA2__USDHC2_DATA2	0x40001382
			MX93_PAD_SD2_DATA3__USDHC2_DATA3	0x40001382
			MX93_PAD_SD2_VSELECT__USDHC2_VSELECT	0x50e
		>;
	};

	/* need to config the SION for data and cmd pad, refer to ERR052021 */
	pinctrl_usdhc2_100mhz: usdhc2-100mhzgrp {
		fsl,pins = <
			MX93_PAD_SD2_CLK__USDHC2_CLK		0x17be
			MX93_PAD_SD2_CMD__USDHC2_CMD		0x4000139e
			MX93_PAD_SD2_DATA0__USDHC2_DATA0	0x4000138e
			MX93_PAD_SD2_DATA1__USDHC2_DATA1	0x4000138e
			MX93_PAD_SD2_DATA2__USDHC2_DATA2	0x4000138e
			MX93_PAD_SD2_DATA3__USDHC2_DATA3	0x4000138e
			MX93_PAD_SD2_VSELECT__USDHC2_VSELECT	0x50e
		>;
	};

	/* need to config the SION for data and cmd pad, refer to ERR052021 */
	pinctrl_usdhc2_200mhz: usdhc2-200mhzgrp {
		fsl,pins = <
			MX93_PAD_SD2_CLK__USDHC2_CLK		0x17fe
			MX93_PAD_SD2_CMD__USDHC2_CMD		0x4000139e
			MX93_PAD_SD2_DATA0__USDHC2_DATA0	0x4000139e
			MX93_PAD_SD2_DATA1__USDHC2_DATA1	0x4000139e
			MX93_PAD_SD2_DATA2__USDHC2_DATA2	0x4000139e
			MX93_PAD_SD2_DATA3__USDHC2_DATA3	0x4000139e
			MX93_PAD_SD2_VSELECT__USDHC2_VSELECT	0x50e
		>;
	};

	pinctrl_usdhc2_sleep: usdhc2grpsleep {
		fsl,pins = <
			MX93_PAD_SD2_CLK__GPIO3_IO01            0x51e
			MX93_PAD_SD2_CMD__GPIO3_IO02		0x51e
			MX93_PAD_SD2_DATA0__GPIO3_IO03		0x51e
			MX93_PAD_SD2_DATA1__GPIO3_IO04		0x51e
			MX93_PAD_SD2_DATA2__GPIO3_IO05		0x51e
			MX93_PAD_SD2_DATA3__GPIO3_IO06		0x51e
			MX93_PAD_SD2_VSELECT__GPIO3_IO19	0x51e
		>;
	};
#endif /* CONFIG_PICOCOREMX93_SD_A */

#ifdef CONFIG_PICOCOREMX93_SD_B
	/* need to config the SION for data and cmd pad, refer to ERR052021 */
	pinctrl_usdhc3: usdhc3grp {
		fsl,pins = <
			MX93_PAD_SD3_CLK__USDHC3_CLK		0x1582
			MX93_PAD_SD3_CMD__USDHC3_CMD		0x40001382
			MX93_PAD_SD3_DATA0__USDHC3_DATA0	0x40001382
			MX93_PAD_SD3_DATA1__USDHC3_DATA1	0x40001382
			MX93_PAD_SD3_DATA2__USDHC3_DATA2	0x40001382
			MX93_PAD_SD3_DATA3__USDHC3_DATA3	0x40001382
		>;
	};

	/* need to config the SION for data and cmd pad, refer to ERR052021 */
	pinctrl_usdhc3_100mhz: usdhc3-100mhzgrp {
		fsl,pins = <
			MX93_PAD_SD3_CLK__USDHC3_CLK		0x158e
			MX93_PAD_SD3_CMD__USDHC3_CMD		0x4000138e
			MX93_PAD_SD3_DATA0__USDHC3_DATA0	0x4000138e
			MX93_PAD_SD3_DATA1__USDHC3_DATA1	0x4000138e
			MX93_PAD_SD3_DATA2__USDHC3_DATA2	0x4000138e
			MX93_PAD_SD3_DATA3__USDHC3_DATA3	0x4000138e
		>;
	};

	/* need to config the SION for data and cmd pad, refer to ERR052021 */
	pinctrl_usdhc3_200mhz: usdhc3-200mhzgrp {
		fsl,pins = <
			MX93_PAD_SD3_CLK__USDHC3_CLK		0x15fe
			MX93_PAD_SD3_CMD__USDHC3_CMD		0x400013fe
			MX93_PAD_SD3_DATA0__USDHC3_DATA0	0x400013fe
			MX93_PAD_SD3_DATA1__USDHC3_DATA1	0x400013fe
			MX93_PAD_SD3_DATA2__USDHC3_DATA2	0x400013fe
			MX93_PAD_SD3_DATA3__USDHC3_DATA3	0x400013fe
		>;
	};

	pinctrl_usdhc3_sleep: usdhc3grpsleep {
		fsl,pins = <
			MX93_PAD_SD3_CLK__GPIO3_IO20		0x31e
			MX93_PAD_SD3_CMD__GPIO3_IO21		0x31e
			MX93_PAD_SD3_DATA0__GPIO3_IO22		0x31e
			MX93_PAD_SD3_DATA1__GPIO3_IO23		0x31e
			MX93_PAD_SD3_DATA2__GPIO3_IO24		0x31e
			MX93_PAD_SD3_DATA3__GPIO3_IO25		0x31e
		>;
	};

	pinctrl_usdhc3_wlan: usdhc3wlangrp {
		fsl,pins = <
			/* WLAN_RST */
			MX93_PAD_CCM_CLKO1__GPIO3_IO26		0x31e
			/* WLAN_WAKE_DEV */
			MX93_PAD_GPIO_IO25__GPIO2_IO25		0x31e
			/* WLAN_WAKE_HOST */
			MX93_PAD_CCM_CLKO1__GPIO3_IO26		0x31e
		>;
	};
#endif /* CONFIG_PICOCOREMX93_SD_B */

	pinctrl_pmic: pmicirq {
		fsl,pins = <
			MX93_PAD_CCM_CLKO2__GPIO3_IO27		0x31e
		>;
	};

#ifdef CONFIG_PICOCOREMX93_UART_C
	pinctrl_uart1: uart1grp {
		fsl,pins = <
			MX93_PAD_UART1_RXD__LPUART1_RX			0x31e
			MX93_PAD_UART1_TXD__LPUART1_TX			0x31e
		>;
	};
#endif /* CONFIG_PICOCOREMX93_UART_C */

#ifdef CONFIG_PICOCOREMX93_UART_A
	pinctrl_uart7: uart7grp {
		fsl,pins = <
			MX93_PAD_GPIO_IO09__LPUART7_RX			0x31e
			MX93_PAD_GPIO_IO08__LPUART7_TX			0x31e
#ifdef CONFIG_PICOCOREMX93_UART_A_RTSCTS
			MX93_PAD_GPIO_IO10__LPUART7_CTS_B		0x31e
			MX93_PAD_GPIO_IO11__LPUART7_RTS_B		0x31e
#endif /* CONFIG_PICOCOREMX93_UART_A_RTSCTS */
		>;
	};
#endif /* CONFIG_PICOCOREMX93_UART_A */

#ifdef CONFIG_PICOCOREMX93_UART_D
	pinctrl_uart2: uart2grp {
		fsl,pins = <
			MX93_PAD_UART2_TXD__LPUART2_TX			0x31e
			MX93_PAD_UART2_RXD__LPUART2_RX			0x31e
		>;
	};
#endif /* CONFIG_PICOCOREMX93_UART_A */

#ifdef CONFIG_PICOCOREMX93_UART_B
	pinctrl_uart6: uart6grp {
		fsl,pins = <
			MX93_PAD_GPIO_IO04__LPUART6_TX		0x31e
			MX93_PAD_GPIO_IO05__LPUART6_RX		0x31e
#ifdef CONFIG_PICOCOREMX93_UART_B_RTSCTS
			MX93_PAD_GPIO_IO06__LPUART6_CTS_B		0x31e
			MX93_PAD_GPIO_IO07__LPUART6_RTS_B		0x31e
#endif /* CONFIG_PICOCOREMX93_UART_B_RTSCTS */
		>;
	};

	pinctrl_uart6_bt: uart6btgrp {
		fsl,pins = <
			/* BT_WAKE_DEV */
			MX93_PAD_GPIO_IO27__GPIO2_IO27		0x31e
			/* BT_WAKE_HOST */
			MX93_PAD_CCM_CLKO3__GPIO4_IO28		0x31e
		>;
	};
#endif /* CONFIG_PICOCOREMX93_UART_B */

#ifdef CONFIG_PICOCOREMX93_I2S_A
	pinctrl_sai3: sai3grp {
		fsl,pins = <
			MX93_PAD_GPIO_IO17__SAI3_MCLK		0x31e
			MX93_PAD_GPIO_IO26__SAI3_TX_SYNC		0x31e
			MX93_PAD_GPIO_IO16__SAI3_TX_BCLK		0x31e
			MX93_PAD_GPIO_IO20__SAI3_RX_DATA00		0x31e
			MX93_PAD_GPIO_IO21__SAI3_TX_DATA00		0x31e
		>;
	};

	pinctrl_sai3_sleep: sai3grpsleep {
		fsl,pins = <
			MX93_PAD_GPIO_IO17__GPIO2_IO17		0x51e
			MX93_PAD_GPIO_IO26__GPIO2_IO26		0x51e
			MX93_PAD_GPIO_IO16__GPIO2_IO16		0x51e
			MX93_PAD_GPIO_IO20__GPIO2_IO20		0x51e
			MX93_PAD_GPIO_IO21__GPIO2_IO21		0x51e
		>;
	};
#endif /* CONFIG_PICOCOREMX93_I2S_A */

#ifdef CONFIG_PICOCOREMX93_PWM_A
	pinctrl_tpm3: tpm3grp {
		fsl,pins = <
			MX93_PAD_GPIO_IO24__TPM3_CH3		0x02
		>;
	};
#endif /* CONFIG_PICOCOREMX93_PWM_A */

#ifdef CONFIG_PICOCOREMX93_BL_CTRL
	pinctrl_tpm5: tpm5grp {
		fsl,pins = <
			MX93_PAD_GPIO_IO18__TPM5_CH2		0x02
		>;
	};
#endif /* CONFIG_PICOCOREMX93_BL_CTRL */
};
